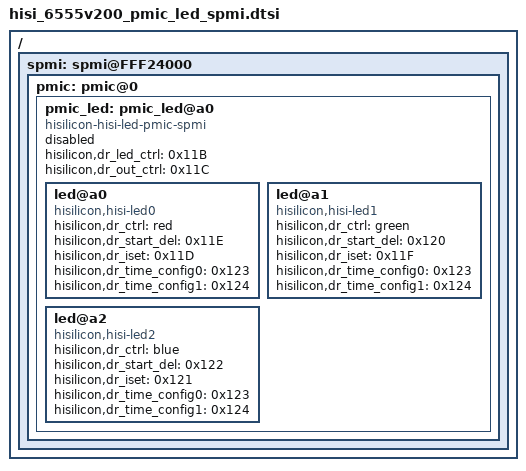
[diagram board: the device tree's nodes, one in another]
/*
 * Copyright (c) 2012-2013, The Linux Foundation. All rights reserved.
 *
 * This program is free software; you can redistribute it and/or modify
 * it under the terms of the GNU General Public License version 2 and
 * only version 2 as published by the Free Software Foundation.
 *
 * This program is distributed in the hope that it will be useful,
 * but WITHOUT ANY WARRANTY; without even the implied warranty of
 * MERCHANTABILITY or FITNESS FOR A PARTICULAR PURPOSE.  See the
 * GNU General Public License for more details.
 */

/ {
spmi: spmi@FFF24000 {
	pmic: pmic@0 {
		pmic_led: pmic_led@a0 {
			compatible = "hisilicon-hisi-led-pmic-spmi";
			status = "disabled";
			hisilicon,dr_led_ctrl = <0x11B>;
			hisilicon,dr_out_ctrl = <0x11C>;

			led@a0 {
				compatible = "hisilicon,hisi-led0";
				hisilicon,dr_ctrl = "red";
				hisilicon,dr_start_del = <0x11E>;
				hisilicon,dr_iset = <0x11D>;
				hisilicon,dr_time_config0 = <0x123>;
				hisilicon,dr_time_config1 = <0x124>;
			};

			led@a1 {
				compatible = "hisilicon,hisi-led1";
				hisilicon,dr_ctrl = "green";
				hisilicon,dr_start_del = <0x120>;
				hisilicon,dr_iset = <0x11F>;
				hisilicon,dr_time_config0 = <0x123>;
				hisilicon,dr_time_config1 = <0x124>;
            };

			led@a2 {
				compatible = "hisilicon,hisi-led2";
				hisilicon,dr_ctrl = "blue";
				hisilicon,dr_start_del = <0x122>;
				hisilicon,dr_iset = <0x121>;
				hisilicon,dr_time_config0 = <0x123>;
				hisilicon,dr_time_config1 = <0x124>;
            };
        };
    };
};
};
